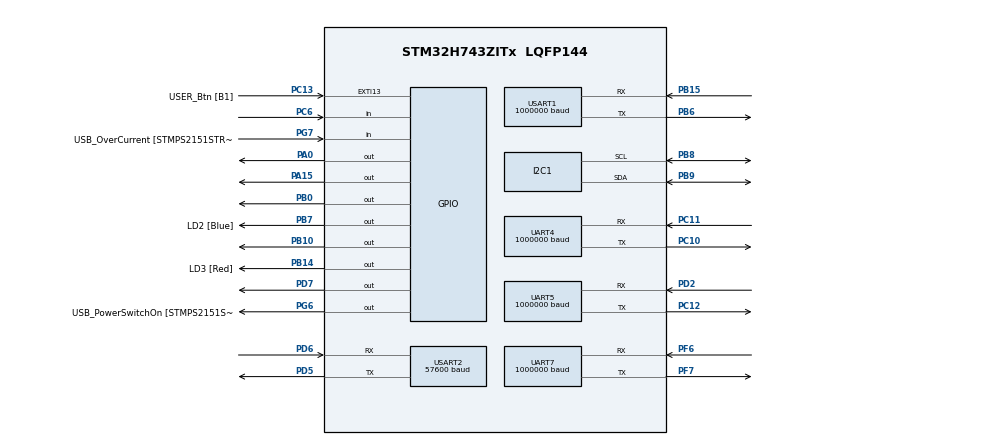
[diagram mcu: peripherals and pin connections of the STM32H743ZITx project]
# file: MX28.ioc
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CORTEX_M7.CPU_DCache=Disabled
CORTEX_M7.CPU_ICache=Disabled
Dma.Request0=UART4_TX
Dma.UART4_TX.0.Direction=DMA_MEMORY_TO_PERIPH
Dma.UART4_TX.0.EventEnable=DISABLE
Dma.UART4_TX.0.FIFOMode=DMA_FIFOMODE_DISABLE
Dma.UART4_TX.0.Instance=DMA1_Stream0
Dma.UART4_TX.0.MemDataAlignment=DMA_MDATAALIGN_BYTE
Dma.UART4_TX.0.MemInc=DMA_MINC_ENABLE
Dma.UART4_TX.0.Mode=DMA_NORMAL
Dma.UART4_TX.0.PeriphDataAlignment=DMA_PDATAALIGN_BYTE
Dma.UART4_TX.0.PeriphInc=DMA_PINC_DISABLE
Dma.UART4_TX.0.Polarity=HAL_DMAMUX_REQ_GEN_RISING
Dma.UART4_TX.0.Priority=DMA_PRIORITY_LOW
Dma.UART4_TX.0.RequestNumber=1
Dma.UART4_TX.0.SyncEnable=DISABLE
Dma.UART4_TX.0.SyncPolarity=HAL_DMAMUX_SYNC_NO_EVENT
Dma.UART4_TX.0.SyncRequestNumber=1
Mcu.Family=STM32H7
Mcu.Name=STM32H743ZITx
Mcu.Package=LQFP144
NVIC.DMA1_Stream0_IRQn=true\:0\:0\:false\:false\:true\:false
NVIC.PriorityGroup=NVIC_PRIORITYGROUP_4
NVIC.TIM1_UP_IRQn=true\:0\:0\:false\:false\:true\:false
NVIC.TimeBase=TIM1_UP_IRQn
NVIC.TimeBaseIP=TIM1
PA0-WKUP.GPIO_Speed=GPIO_SPEED_FREQ_VERY_HIGH
PA0-WKUP.PinState=GPIO_PIN_SET
PA0-WKUP.Signal=GPIO_Output
PA10.GPIO_Label=USB_ID
PA10.Signal=USB_OTG_FS_ID
PA11.GPIO_Label=USB_DM
PA11.Signal=USB_OTG_FS_DM
PA12.GPIO_Label=USB_DP
PA12.Signal=USB_OTG_FS_DP
PA13.GPIO_Label=TMS
PA13.Mode=Trace_Asynchronous_SW
PA13.Signal=SYS_JTMS-SWDIO
PA14.GPIO_Label=TCK
PA14.Mode=Trace_Asynchronous_SW
PA14.Signal=SYS_JTCK-SWCLK
PA15.GPIO_Speed=GPIO_SPEED_FREQ_VERY_HIGH
PA15.PinState=GPIO_PIN_SET
PA15.Signal=GPIO_Output
PA8.GPIO_Label=USB_SOF [TP1]
PA8.Signal=USB_OTG_FS_SOF
PA9.GPIO_Label=USB_VBUS
PA9.Signal=USB_OTG_FS_VBUS
PB0.GPIO_Speed=GPIO_SPEED_FREQ_VERY_HIGH
PB0.Signal=GPIO_Output
PB10.GPIO_Speed=GPIO_SPEED_FREQ_VERY_HIGH
PB10.Signal=GPIO_Output
PB14.GPIO_Label=LD3 [Red]
PB14.Signal=GPIO_Output
PB15.Mode=Asynchronous
PB15.Signal=USART1_RX
PB3.GPIO_Label=SWO
PB3.Mode=Trace_Asynchronous_SW
PB3.Signal=SYS_JTDO-SWO
PB6.Mode=Asynchronous
PB6.Signal=USART1_TX
PB7.GPIO_Label=LD2 [Blue]
PB7.Signal=GPIO_Output
PB8.Mode=I2C
PB8.Signal=I2C1_SCL
PB9.Mode=I2C
PB9.Signal=I2C1_SDA
PC10.Mode=Asynchronous
PC10.Signal=UART4_TX
PC11.Mode=Asynchronous
PC11.Signal=UART4_RX
PC12.Mode=Asynchronous
PC12.Signal=UART5_TX
PC13.GPIO_Label=USER_Btn [B1]
PC13.Signal=GPXTI13
PC14-OSC32_IN.Signal=RCC_OSC32_IN
PC15-OSC32_OUT.Signal=RCC_OSC32_OUT
PC6.Signal=GPIO_Input
PD2.Mode=Asynchronous
PD2.Signal=UART5_RX
PD5.Mode=Asynchronous
PD5.Signal=USART2_TX
PD6.Mode=Asynchronous
PD6.Signal=USART2_RX
PD7.GPIO_Speed=GPIO_SPEED_FREQ_VERY_HIGH
PD7.Signal=GPIO_Output
PD8.GPIO_Label=STLK_RX [STM32F103CBT6_PA3]
PD8.Signal=USART3_TX
PD9.GPIO_Label=STLK_TX [STM32F103CBT6_PA2]
PD9.Signal=USART3_RX
PF6.Mode=Asynchronous
PF6.Signal=UART7_RX
PF7.Mode=Asynchronous
PF7.Signal=UART7_TX
PG6.GPIO_Label=USB_PowerSwitchOn [STMPS2151STR_EN]
PG6.Signal=GPIO_Output
PG7.GPIO_Label=USB_OverCurrent [STMPS2151STR_FAULT]
PG7.Signal=GPIO_Input
PH0-OSC_IN.GPIO_Label=MCO
PH0-OSC_IN.Signal=RCC_OSC_IN
PH1-OSC_OUT.Signal=RCC_OSC_OUT
ProjectManager.HeapSize=0x200
ProjectManager.StackSize=0x400
ProjectManager.TargetToolchain=SW4STM32
RCC.48MHZClocksFreq_Value=24000000
RCC.ADCFreq_Value=129000000
RCC.AHBFreq_Value=16000000
RCC.APB1CLKDivider=RCC_HCLK_DIV2
RCC.APB1Freq_Value=64000000
RCC.APB1TimFreq_Value=16000000
RCC.APB2Freq_Value=64000000
RCC.APB2TimFreq_Value=16000000
RCC.APB3Freq_Value=64000000
RCC.APB4Freq_Value=64000000
RCC.CortexFreq_Value=64000000
RCC.HCLKFreq_Value=64000000
RCC.HSE_VALUE=25000000
RCC.HSI_VALUE=64000000
RCC.LSE_VALUE=32768
RCC.PLLMUL=RCC_PLL_MUL9
RCC.PRESCALERUSB=RCC_USBCLKSOURCE_PLL_DIV1_5
RCC.SYSCLKFreq_VALUE=64000000
RCC.SYSCLKSourceVirtual=RCC_SYSCLKSOURCE_PLLCLK
RCC.USBFreq_Value=129000000
RCC.VCOOutputFreq_Value=192000000
UART4.BaudRate=1000000
UART4.WordLength=WORDLENGTH_8B
UART5.BaudRate=1000000
UART5.WordLength=WORDLENGTH_8B
UART7.BaudRate=1000000
UART7.WordLength=WORDLENGTH_8B
USART1.BaudRate=1000000
USART1.VirtualMode-Asynchronous=VM_ASYNC
USART1.WordLength=WORDLENGTH_8B
USART2.BaudRate=57600
USART2.VirtualMode-Asynchronous=VM_ASYNC
USART2.WordLength=WORDLENGTH_8B
VP_SYS_VS_tim1.Mode=TIM1
board=NUCLEO-H743ZI

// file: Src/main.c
/**
  ******************************************************************************
  * @file           : main.c
  * @brief          : Main program body
  ******************************************************************************
  ** This notice applies to any and all portions of this file
  * that are not between comment pairs USER CODE BEGIN and
  * USER CODE END. Other portions of this file, whether
  * inserted by the user or by software development tools
  * are owned by their respective copyright owners.
  *
  * COPYRIGHT(c) 2018 STMicroelectronics
  *
  * Redistribution and use in source and binary forms, with or without modification,
  * are permitted provided that the following conditions are met:
  *   1. Redistributions of source code must retain the above copyright notice,
  *      this list of conditions and the following disclaimer.
  *   2. Redistributions in binary form must reproduce the above copyright notice,
  *      this list of conditions and the following disclaimer in the documentation
  *      and/or other materials provided with the distribution.
  *   3. Neither the name of STMicroelectronics nor the names of its contributors
  *      may be used to endorse or promote products derived from this software
  *      without specific prior written permission.
  *
  * THIS SOFTWARE IS PROVIDED BY THE COPYRIGHT HOLDERS AND CONTRIBUTORS "AS IS"
  * AND ANY EXPRESS OR IMPLIED WARRANTIES, INCLUDING, BUT NOT LIMITED TO, THE
  * IMPLIED WARRANTIES OF MERCHANTABILITY AND FITNESS FOR A PARTICULAR PURPOSE ARE
  * DISCLAIMED. IN NO EVENT SHALL THE COPYRIGHT HOLDER OR CONTRIBUTORS BE LIABLE
  * FOR ANY DIRECT, INDIRECT, INCIDENTAL, SPECIAL, EXEMPLARY, OR CONSEQUENTIAL
  * DAMAGES (INCLUDING, BUT NOT LIMITED TO, PROCUREMENT OF SUBSTITUTE GOODS OR
  * SERVICES; LOSS OF USE, DATA, OR PROFITS; OR BUSINESS INTERRUPTION) HOWEVER
  * CAUSED AND ON ANY THEORY OF LIABILITY, WHETHER IN CONTRACT, STRICT LIABILITY,
  * OR TORT (INCLUDING NEGLIGENCE OR OTHERWISE) ARISING IN ANY WAY OUT OF THE USE
  * OF THIS SOFTWARE, EVEN IF ADVISED OF THE POSSIBILITY OF SUCH DAMAGE.
  *
  ******************************************************************************
  */
#include "main.h"
#include "stm32h7xx_hal.h"
#include "dma.h"
#include "i2c.h"
#include "usart.h"
#include "gpio.h"

/* USER CODE BEGIN Includes */
#include "../Drivers/Dynamixel/DynamixelProtocolV1.h"
/* USER CODE END Includes */

/* USER CODE BEGIN PV */
/* Private variables ---------------------------------------------------------*/

/* USER CODE END PV */

void SystemClock_Config(void);

/* USER CODE BEGIN PFP */
/* Private function prototypes -----------------------------------------------*/

/* USER CODE END PFP */

int main(void)
{

  /* MCU Configuration----------------------------------------------------------*/

  /* Reset of all peripherals, Initializes the Flash interface and the Systick. */
  HAL_Init();

  /* Configure the system clock */
  SystemClock_Config();

  /* Initialize all configured peripherals */
  MX_GPIO_Init();
  MX_DMA_Init();
  MX_UART7_Init();
  MX_UART4_Init();
  MX_USART1_UART_Init();
  MX_USART2_UART_Init();
  MX_UART5_Init();
  MX_I2C1_Init();
  /* USER CODE BEGIN 2 */
  Dynamixel_HandleTypeDef MX28;
  Dynamixel_Init(&MX28, 1, &huart5, GPIOB, GPIO_PIN_0, MX28TYPE);

  /* Configure motor to return status packets only for read commands */
  Dynamixel_SetStatusReturnLevel(&MX28, 1);
  HAL_Delay(10);

  /* Set minimum delay return time (2 microseconds) */
  Dynamixel_SetReturnDelayTime(&MX28, 2);
  HAL_Delay(10);

  /* Impress current to motor to enable torque */
  Dynamixel_TorqueEnable(&MX28, 1);

  /* Set a position */
  Dynamixel_SetGoalPosition(&MX28, 270);
  /* USER CODE END 2 */

  /* Infinite loop */
  while (1)
  {

  }

}

void SystemClock_Config(void)
{

  RCC_OscInitTypeDef RCC_OscInitStruct;
  RCC_ClkInitTypeDef RCC_ClkInitStruct;
  RCC_PeriphCLKInitTypeDef PeriphClkInitStruct;

    /**Supply configuration update enable
    */
  MODIFY_REG(PWR->CR3, PWR_CR3_SCUEN, 0);

    /**Configure the main internal regulator output voltage
    */
  __HAL_PWR_VOLTAGESCALING_CONFIG(PWR_REGULATOR_VOLTAGE_SCALE1);

  while ((PWR->D3CR & (PWR_D3CR_VOSRDY)) != PWR_D3CR_VOSRDY)
  {

  }
    /**Initializes the CPU, AHB and APB busses clocks
    */
  RCC_OscInitStruct.OscillatorType = RCC_OSCILLATORTYPE_HSI;
  RCC_OscInitStruct.HSIState = RCC_HSI_DIV1;
  RCC_OscInitStruct.HSICalibrationValue = 16;
  RCC_OscInitStruct.PLL.PLLState = RCC_PLL_NONE;
  if (HAL_RCC_OscConfig(&RCC_OscInitStruct) != HAL_OK)
  {
    _Error_Handler(__FILE__, __LINE__);
  }

    /**Initializes the CPU, AHB and APB busses clocks
    */
  RCC_ClkInitStruct.ClockType = RCC_CLOCKTYPE_HCLK|RCC_CLOCKTYPE_SYSCLK
                              |RCC_CLOCKTYPE_PCLK1|RCC_CLOCKTYPE_PCLK2
                              |RCC_CLOCKTYPE_D3PCLK1|RCC_CLOCKTYPE_D1PCLK1;
  RCC_ClkInitStruct.SYSCLKSource = RCC_SYSCLKSOURCE_HSI;
  RCC_ClkInitStruct.SYSCLKDivider = RCC_SYSCLK_DIV1;
  RCC_ClkInitStruct.AHBCLKDivider = RCC_HCLK_DIV1;
  RCC_ClkInitStruct.APB3CLKDivider = RCC_APB3_DIV1;
  RCC_ClkInitStruct.APB1CLKDivider = RCC_APB1_DIV1;
  RCC_ClkInitStruct.APB2CLKDivider = RCC_APB2_DIV1;
  RCC_ClkInitStruct.APB4CLKDivider = RCC_APB4_DIV1;

  if (HAL_RCC_ClockConfig(&RCC_ClkInitStruct, FLASH_LATENCY_0) != HAL_OK)
  {
    _Error_Handler(__FILE__, __LINE__);
  }

  PeriphClkInitStruct.PeriphClockSelection = RCC_PERIPHCLK_USART2|RCC_PERIPHCLK_UART4
                              |RCC_PERIPHCLK_UART7|RCC_PERIPHCLK_USART1
                              |RCC_PERIPHCLK_UART5|RCC_PERIPHCLK_I2C1;
  PeriphClkInitStruct.Usart234578ClockSelection = RCC_USART234578CLKSOURCE_D2PCLK1;
  PeriphClkInitStruct.Usart16ClockSelection = RCC_USART16CLKSOURCE_D2PCLK2;
  PeriphClkInitStruct.I2c123ClockSelection = RCC_I2C123CLKSOURCE_D2PCLK1;
  if (HAL_RCCEx_PeriphCLKConfig(&PeriphClkInitStruct) != HAL_OK)
  {
    _Error_Handler(__FILE__, __LINE__);
  }

    /**Configure the Systick interrupt time
    */
  HAL_SYSTICK_Config(SystemCoreClock/1000);

    /**Configure the Systick
    */
  HAL_SYSTICK_CLKSourceConfig(SYSTICK_CLKSOURCE_HCLK);

  /* SysTick_IRQn interrupt configuration */
  HAL_NVIC_SetPriority(SysTick_IRQn, 0, 0);
}

void HAL_TIM_PeriodElapsedCallback(TIM_HandleTypeDef *htim)
{
  if (htim->Instance == TIM1) {
    HAL_IncTick();
  }
}

void _Error_Handler(char *file, int line)
{
  while(1)
  {
  }
}

/************************ (C) COPYRIGHT STMicroelectronics *****END OF FILE****/
